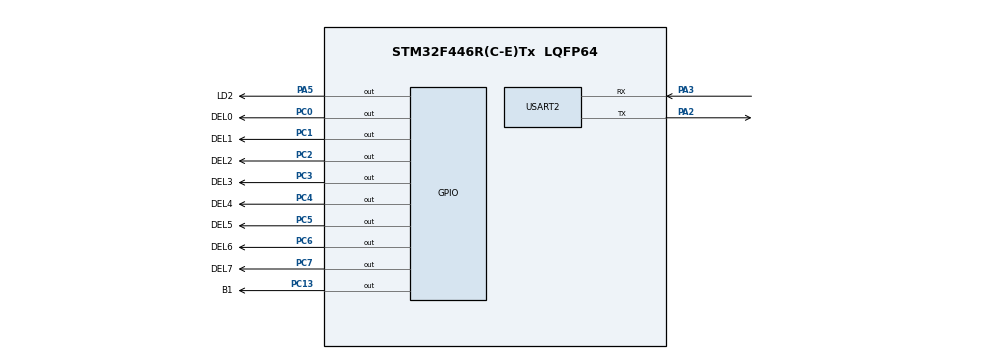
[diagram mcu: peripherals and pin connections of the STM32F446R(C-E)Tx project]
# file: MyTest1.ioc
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Mcu.Family=STM32F4
Mcu.Name=STM32F446R(C-E)Tx
Mcu.Package=LQFP64
NVIC.PriorityGroup=NVIC_PRIORITYGROUP_4
PA2.Mode=Asynchronous
PA2.Signal=USART2_TX
PA3.Mode=Asynchronous
PA3.Signal=USART2_RX
PA5.GPIO_Label=LD2
PA5.Signal=GPIO_Output
PC0.GPIO_Label=DEL0
PC0.Signal=GPIO_Output
PC1.GPIO_Label=DEL1
PC1.Signal=GPIO_Output
PC13.GPIO_Label=B1
PC13.Signal=GPIO_Output
PC2.GPIO_Label=DEL2
PC2.Signal=GPIO_Output
PC3.GPIO_Label=DEL3
PC3.Signal=GPIO_Output
PC4.GPIO_Label=DEL4
PC4.Signal=GPIO_Output
PC5.GPIO_Label=DEL5
PC5.Signal=GPIO_Output
PC6.GPIO_Label=DEL6
PC6.Signal=GPIO_Output
PC7.GPIO_Label=DEL7
PC7.Signal=GPIO_Output
ProjectManager.HeapSize=0x200
ProjectManager.StackSize=0x400
ProjectManager.TargetToolchain=MDK-ARM V5.32
RCC.CortexFreq_Value=16000000
RCC.USBFreq_Value=96000000
RCC.VCOOutputFreq_Value=192000000
USART2.VirtualMode=VM_ASYNC
board=custom

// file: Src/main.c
/* USER CODE BEGIN Header */
/**
  ******************************************************************************
  * @file           : main.c
  * @brief          : Main program body
  ******************************************************************************
  * @attention
  *
  * Copyright (c) 2024 STMicroelectronics.
  * All rights reserved.
  *
  * This software is licensed under terms that can be found in the LICENSE file
  * in the root directory of this software component.
  * If no LICENSE file comes with this software, it is provided AS-IS.
  *
  ******************************************************************************
  */
/* USER CODE END Header */
#include "main.h"
#include "usart.h"
#include "gpio.h"

/* USER CODE BEGIN Includes */
#include "stdio.h"
/* USER CODE END Includes */

void SystemClock_Config(void);
/* USER CODE BEGIN PFP */
int MY_SUM(int a, int b, int c, int d);
/* USER CODE END PFP */

/* USER CODE BEGIN 0 */
int fputc(int ch, FILE* f){
  HAL_UART_Transmit(&huart2, (uint8_t*) &ch, 1, 0xFFFF );
  return ch;
}
/* USER CODE END 0 */

int main(void)
{

  /* MCU Configuration--------------------------------------------------------*/

  /* Reset of all peripherals, Initializes the Flash interface and the Systick. */
  HAL_Init();

  /* Configure the system clock */
  SystemClock_Config();

  /* Initialize all configured peripherals */
  MX_GPIO_Init();
  MX_USART2_UART_Init();
  /* USER CODE BEGIN 2 */
  int cnt = 0;
  /* USER CODE END 2 */

  /* Infinite loop */
  while (1)
  {
    int result = MY_SUM(cnt, 1,2,3);
    printf("TEST %i+1+2+3=%i\r\n", cnt, result);
    ++cnt;
    HAL_Delay(1000);
  }
}

void SystemClock_Config(void)
{
  RCC_OscInitTypeDef RCC_OscInitStruct = {0};
  RCC_ClkInitTypeDef RCC_ClkInitStruct = {0};

  /** Configure the main internal regulator output voltage
  */
  __HAL_RCC_PWR_CLK_ENABLE();
  __HAL_PWR_VOLTAGESCALING_CONFIG(PWR_REGULATOR_VOLTAGE_SCALE3);

  /** Initializes the RCC Oscillators according to the specified parameters
  * in the RCC_OscInitTypeDef structure.
  */
  RCC_OscInitStruct.OscillatorType = RCC_OSCILLATORTYPE_HSI;
  RCC_OscInitStruct.HSIState = RCC_HSI_ON;
  RCC_OscInitStruct.HSICalibrationValue = RCC_HSICALIBRATION_DEFAULT;
  RCC_OscInitStruct.PLL.PLLState = RCC_PLL_NONE;
  if (HAL_RCC_OscConfig(&RCC_OscInitStruct) != HAL_OK)
  {
    Error_Handler();
  }

  /** Initializes the CPU, AHB and APB buses clocks
  */
  RCC_ClkInitStruct.ClockType = RCC_CLOCKTYPE_HCLK|RCC_CLOCKTYPE_SYSCLK
                              |RCC_CLOCKTYPE_PCLK1|RCC_CLOCKTYPE_PCLK2;
  RCC_ClkInitStruct.SYSCLKSource = RCC_SYSCLKSOURCE_HSI;
  RCC_ClkInitStruct.AHBCLKDivider = RCC_SYSCLK_DIV1;
  RCC_ClkInitStruct.APB1CLKDivider = RCC_HCLK_DIV1;
  RCC_ClkInitStruct.APB2CLKDivider = RCC_HCLK_DIV1;

  if (HAL_RCC_ClockConfig(&RCC_ClkInitStruct, FLASH_LATENCY_0) != HAL_OK)
  {
    Error_Handler();
  }
}

void Error_Handler(void)
{
  __disable_irq();
  while (1)
  {
  }
}
